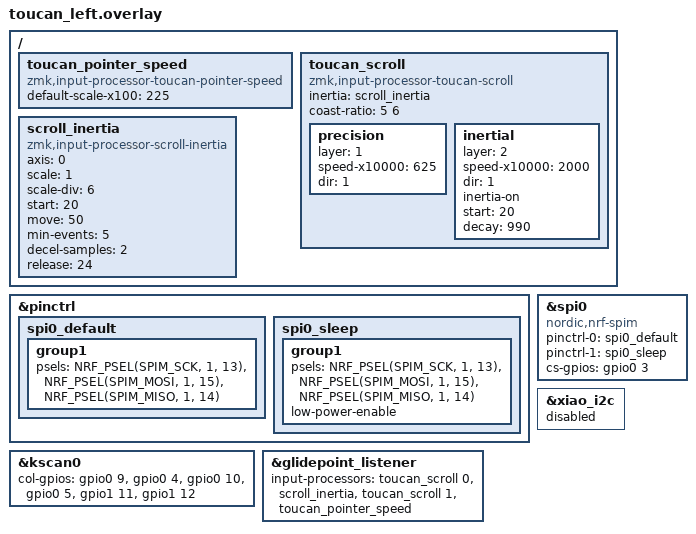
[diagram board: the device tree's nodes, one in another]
#include "toucan.dtsi"

/ {
    // Pointer speed adjustable from the Toucan Studio app (toucan-studio firmware module).
    // 225 = the previous `&zip_xy_scaler 9 4`.
    toucan_pointer_speed: toucan_pointer_speed {
        compatible = "zmk,input-processor-toucan-pointer-speed";
        #input-processor-cells = <0>;
        default-scale-x100 = <225>;
    };

    // Per-layer trackpad scrolling adjustable from the Toucan Studio app. The children
    // reproduce the previous layer overrides: layer 1 = precision (Y_INVERT, 1/16),
    // layer 2 = inertia (Y_INVERT, 1/5, coasting at 5/6). Other layers keep the cursor.
    toucan_scroll: toucan_scroll {
        compatible = "zmk,input-processor-toucan-scroll";
        #input-processor-cells = <1>;
        inertia = <&scroll_inertia>;
        coast-ratio = <5 6>;

        precision {
            layer = <1>;
            speed-x10000 = <625>;
            dir = <1>;
        };

        inertial {
            layer = <2>;
            speed-x10000 = <2000>;
            dir = <1>;
            inertia-on;
            start = <20>;
            decay = <990>;
        };
    };

    scroll_inertia: scroll_inertia {
        compatible = "zmk,input-processor-scroll-inertia";
        #input-processor-cells = <0>;
        axis = <0>;
        scale = <1>;
        scale-div = <6>;
        start = <20>;
        move = <50>;
        min-events = <5>;
        decel-samples = <2>;
        release = <24>;
    };
};

&pinctrl {
    spi0_default: spi0_default {
        group1 {
            psels = <NRF_PSEL(SPIM_SCK, 1, 13)>,
                <NRF_PSEL(SPIM_MOSI, 1, 15)>,
                <NRF_PSEL(SPIM_MISO, 1, 14)>;
        };
    };

     spi0_sleep: spi0_sleep {
        group1 {
            psels = <NRF_PSEL(SPIM_SCK, 1, 13)>,
                    <NRF_PSEL(SPIM_MOSI, 1, 15)>,
                    <NRF_PSEL(SPIM_MISO, 1, 14)>;
            low-power-enable;
        };
    };

};

nice_view_spi: &spi0 {
   compatible = "nordic,nrf-spim";
   pinctrl-0 = <&spi0_default>;
   pinctrl-1 = <&spi0_sleep>;
   pinctrl-names = "default", "sleep";
   cs-gpios = <&gpio0 3 GPIO_ACTIVE_HIGH>;
};

&xiao_i2c {
    status = "disabled";
};

&kscan0 {
    col-gpios
    = <&gpio0 9 GPIO_ACTIVE_HIGH>
    , <&gpio0 4 GPIO_ACTIVE_HIGH>
    , <&gpio0 10 GPIO_ACTIVE_HIGH>
    , <&gpio0 5 GPIO_ACTIVE_HIGH>
    , <&gpio1 11 GPIO_ACTIVE_HIGH>
    , <&gpio1 12 GPIO_ACTIVE_HIGH>
    ;
};

&glidepoint_listener {
    status = "okay";
    // Scrolling layers turn X/Y into wheel events before the pointer speed applies.
    input-processors = <&toucan_scroll 0 &scroll_inertia &toucan_scroll 1 &toucan_pointer_speed>;

    /delete-node/ scroller;

};
